# STM32H757_CM7 register map
File version: 1.3
CPU: CM7 r0p1, little endian, MPU, FPU, 4 interrupt priority bits
Registers are 32-bit, read-write, reset 0x0 unless marked. A register's access mark holds for its fields unless they carry their own. Offsets are from the block's base; [hi:lo] are bit positions.

## Ethernet_DMA
Base 0x40029000
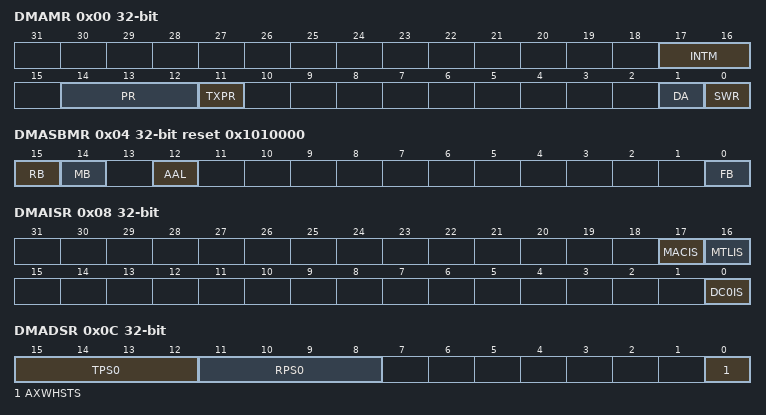
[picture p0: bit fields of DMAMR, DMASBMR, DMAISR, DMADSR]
0x00 DMAMR access not given — DMA mode register
  [17:16] INTM — Interrupt Mode
  [14:12] PR rw — Priority ratio
  [11] TXPR rw — Transmit priority
  [1] DA rw — DMA Tx or Rx Arbitration Scheme
  [0] SWR — Software Reset
0x04 DMASBMR access not given reset 0x1010000 — System bus mode register
  [15] RB rw — Rebuild INCRx Burst
  [14] MB rw — Mixed Burst
  [12] AAL — Address-Aligned Beats
  [0] FB — Fixed Burst Length
0x08 DMAISR access not given — Interrupt status register
  [17] MACIS — MAC Interrupt Status
  [16] MTLIS — MTL Interrupt Status
  [0] DC0IS — DMA Channel Interrupt Status
0x0C DMADSR access not given — Debug status register
  [15:12] TPS0 — DMA Channel Transmit Process State
  [11:8] RPS0 — DMA Channel Receive Process State
  [0] AXWHSTS — AHB Master Write Channel
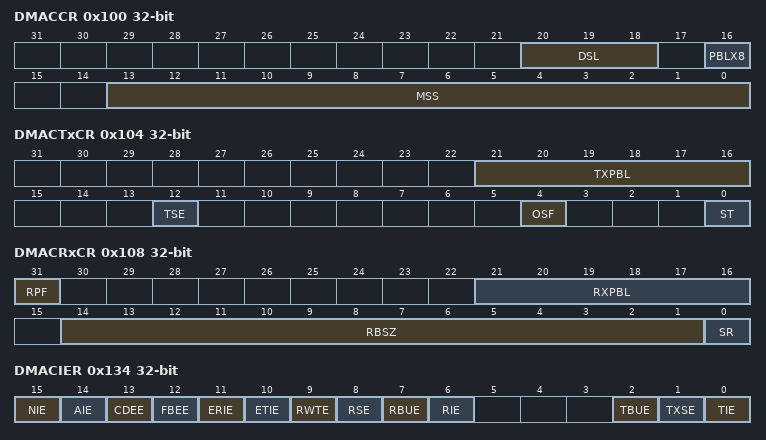
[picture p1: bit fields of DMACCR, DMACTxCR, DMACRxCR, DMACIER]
0x100 DMACCR access not given — Channel control register
  [20:18] DSL — Descriptor Skip Length
  [16] PBLX8 — 8xPBL mode
  [13:0] MSS — Maximum Segment Size
0x104 DMACTxCR access not given — Channel transmit control register
  [21:16] TXPBL — Transmit Programmable Burst Length
  [12] TSE — TCP Segmentation Enabled
  [4] OSF — Operate on Second Packet
  [0] ST — Start or Stop Transmission Command
0x108 DMACRxCR access not given — Channel receive control register
  [31] RPF — DMA Rx Channel Packet Flush
  [21:16] RXPBL — Receive Programmable Burst Length
  [14:1] RBSZ — Receive Buffer size
  [0] SR — Start or Stop Receive
0x114 DMACTxDLAR access not given — Channel Tx descriptor list address register
  [31:2] TDESLA — Start of Transmit List
0x11C DMACRxDLAR access not given — Channel Rx descriptor list address register
  [31:2] RDESLA — Start of Receive List
0x120 DMACTxDTPR access not given — Channel Tx descriptor tail pointer register
  [31:2] TDT — Transmit Descriptor Tail Pointer
0x128 DMACRxDTPR access not given — Channel Rx descriptor tail pointer register
  [31:2] RDT — Receive Descriptor Tail Pointer
0x12C DMACTxRLR access not given — Channel Tx descriptor ring length register
  [9:0] TDRL — Transmit Descriptor Ring Length
0x130 DMACRxRLR access not given — Channel Rx descriptor ring length register
  [9:0] RDRL — Receive Descriptor Ring Length
0x134 DMACIER access not given — Channel interrupt enable register
  [15] NIE — Normal Interrupt Summary Enable
  [14] AIE — Abnormal Interrupt Summary Enable
  [13] CDEE — Context Descriptor Error Enable
  [12] FBEE — Fatal Bus Error Enable
  [11] ERIE — Early Receive Interrupt Enable
  [10] ETIE — Early Transmit Interrupt Enable
  [9] RWTE — Receive Watchdog Timeout Enable
  [8] RSE — Receive Stopped Enable
  [7] RBUE — Receive Buffer Unavailable Enable
  [6] RIE — Receive Interrupt Enable
  [2] TBUE — Transmit Buffer Unavailable Enable
  [1] TXSE — Transmit Stopped Enable
  [0] TIE — Transmit Interrupt Enable
0x138 DMACRxIWTR access not given — Channel Rx interrupt watchdog timer register
  [7:0] RWT — Receive Interrupt Watchdog Timer Count
0x144 DMACCATxDR access not given — Channel current application transmit descriptor register
  [31:0] CURTDESAPTR — Application Transmit Descriptor Address Pointer
0x14C DMACCARxDR access not given — Channel current application receive descriptor register
  [31:0] CURRDESAPTR — Application Receive Descriptor Address Pointer
0x154 DMACCATxBR access not given — Channel current application transmit buffer register
  [31:0] CURTBUFAPTR — Application Transmit Buffer Address Pointer
0x15C DMACCARxBR access not given — Channel current application receive buffer register
  [31:0] CURRBUFAPTR — Application Receive Buffer Address Pointer
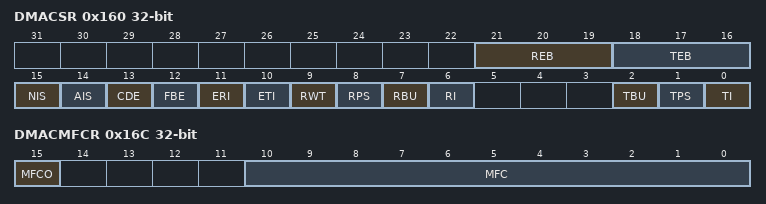
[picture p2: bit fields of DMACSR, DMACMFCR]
0x160 DMACSR access not given — Channel status register
  [21:19] REB — Rx DMA Error Bits
  [18:16] TEB — Tx DMA Error Bits
  [15] NIS — Normal Interrupt Summary
  [14] AIS — Abnormal Interrupt Summary
  [13] CDE — Context Descriptor Error
  [12] FBE — Fatal Bus Error
  [11] ERI — Early Receive Interrupt
  [10] ETI — Early Transmit Interrupt
  [9] RWT — Receive Watchdog Timeout
  [8] RPS — Receive Process Stopped
  [7] RBU — Receive Buffer Unavailable
  [6] RI — Receive Interrupt
  [2] TBU — Transmit Buffer Unavailable
  [1] TPS — Transmit Process Stopped
  [0] TI — Transmit Interrupt
0x16C DMACMFCR access not given — Channel missed frame count register
  [15] MFCO — Overflow status of the MFC Counter
  [10:0] MFC — Dropped Packet Counters
